# TM4C123GH6PM register map
Vendor: Texas Instruments; Series: TM4C; File version: 11073
CPU: CM4 r1p2, little endian, MPU, FPU, 3 interrupt priority bits
Registers are 32-bit, read-write, reset 0x1 unless marked. A register's access mark holds for its fields unless they carry their own. Offsets are from the block's base; [hi:lo] are bit positions; {n}, {i} and the like mark numbered series.

## TIMER0 — Register map for TIMER0 peripheral
Base 0x40030000; register names take the prefix TIMER0
Same registers: TIMER1 0x40031000 (register names take the prefix TIMER1), TIMER2 0x40032000 (register names take the prefix TIMER2), TIMER3 0x40033000 (register names take the prefix TIMER3), TIMER4 0x40034000 (register names take the prefix TIMER4), TIMER5 0x40035000 (register names take the prefix TIMER5), WTIMER1 0x40037000 (register names take the prefix WTIMER1), WTIMER2 0x4004C000 (register names take the prefix WTIMER2), WTIMER3 0x4004D000 (register names take the prefix WTIMER3), WTIMER4 0x4004E000 (register names take the prefix WTIMER4), WTIMER5 0x4004F000 (register names take the prefix WTIMER5)
0x00 CFG (reset mask 0x0) — GPTM Configuration
  [2:0] TIMER_CFG
    0=TIMER_CFG_32_BIT_TIMER (32-bit timer configuration); 1=TIMER_CFG_32_BIT_RTC (32-bit real-time clock (RTC) counter configuration); 4=TIMER_CFG_16_BIT (16-bit timer configuration. The function is controlled by bits 1:0 of GPTMTAMR and GPTMTBMR)
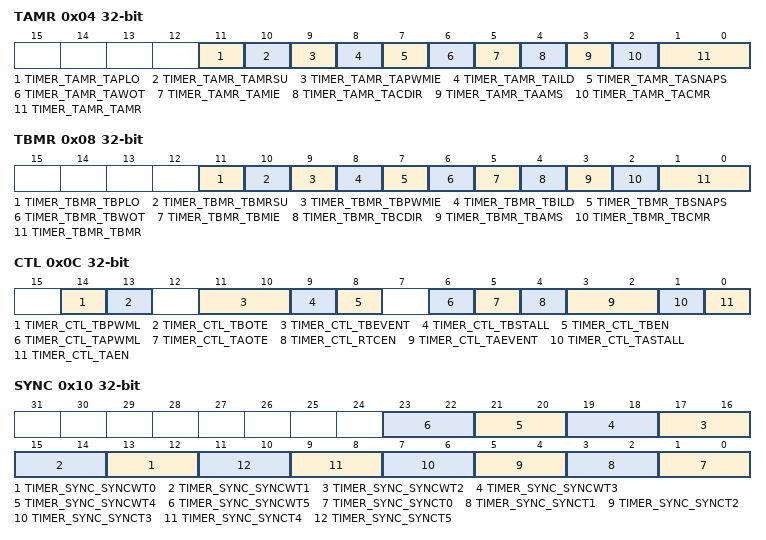
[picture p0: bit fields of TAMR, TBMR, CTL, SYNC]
0x04 TAMR (reset mask 0x0) — GPTM Timer A Mode
  [11] TIMER_TAMR_TAPLO — GPTM Timer A PWM Legacy Operation
  [10] TIMER_TAMR_TAMRSU — GPTM Timer A Match Register Update
  [9] TIMER_TAMR_TAPWMIE — GPTM Timer A PWM Interrupt Enable
  [8] TIMER_TAMR_TAILD — GPTM Timer A Interval Load Write
  [7] TIMER_TAMR_TASNAPS — GPTM Timer A Snap-Shot Mode
  [6] TIMER_TAMR_TAWOT — GPTM Timer A Wait-on-Trigger
  [5] TIMER_TAMR_TAMIE — GPTM Timer A Match Interrupt Enable
  [4] TIMER_TAMR_TACDIR — GPTM Timer A Count Direction
  [3] TIMER_TAMR_TAAMS — GPTM Timer A Alternate Mode Select
  [2] TIMER_TAMR_TACMR — GPTM Timer A Capture Mode
  [1:0] TIMER_TAMR_TAMR — GPTM Timer A Mode
    1=TIMER_TAMR_TAMR_1_SHOT (One-Shot Timer mode); 2=TIMER_TAMR_TAMR_PERIOD (Periodic Timer mode); 3=TIMER_TAMR_TAMR_CAP (Capture mode)
0x08 TBMR (reset mask 0x0) — GPTM Timer B Mode
  [11] TIMER_TBMR_TBPLO — GPTM Timer B PWM Legacy Operation
  [10] TIMER_TBMR_TBMRSU — GPTM Timer B Match Register Update
  [9] TIMER_TBMR_TBPWMIE — GPTM Timer B PWM Interrupt Enable
  [8] TIMER_TBMR_TBILD — GPTM Timer B Interval Load Write
  [7] TIMER_TBMR_TBSNAPS — GPTM Timer B Snap-Shot Mode
  [6] TIMER_TBMR_TBWOT — GPTM Timer B Wait-on-Trigger
  [5] TIMER_TBMR_TBMIE — GPTM Timer B Match Interrupt Enable
  [4] TIMER_TBMR_TBCDIR — GPTM Timer B Count Direction
  [3] TIMER_TBMR_TBAMS — GPTM Timer B Alternate Mode Select
  [2] TIMER_TBMR_TBCMR — GPTM Timer B Capture Mode
  [1:0] TIMER_TBMR_TBMR — GPTM Timer B Mode
    1=TIMER_TBMR_TBMR_1_SHOT (One-Shot Timer mode); 2=TIMER_TBMR_TBMR_PERIOD (Periodic Timer mode); 3=TIMER_TBMR_TBMR_CAP (Capture mode)
0x0C CTL (reset mask 0x0) — GPTM Control
  [14] TIMER_CTL_TBPWML — GPTM Timer B PWM Output Level
  [13] TIMER_CTL_TBOTE — GPTM Timer B Output Trigger Enable
  [11:10] TIMER_CTL_TBEVENT — GPTM Timer B Event Mode
    0=TIMER_CTL_TBEVENT_POS (Positive edge); 1=TIMER_CTL_TBEVENT_NEG (Negative edge); 3=TIMER_CTL_TBEVENT_BOTH (Both edges)
  [9] TIMER_CTL_TBSTALL — GPTM Timer B Stall Enable
  [8] TIMER_CTL_TBEN — GPTM Timer B Enable
  [6] TIMER_CTL_TAPWML — GPTM Timer A PWM Output Level
  [5] TIMER_CTL_TAOTE — GPTM Timer A Output Trigger Enable
  [4] TIMER_CTL_RTCEN — GPTM RTC Stall Enable
  [3:2] TIMER_CTL_TAEVENT — GPTM Timer A Event Mode
    0=TIMER_CTL_TAEVENT_POS (Positive edge); 1=TIMER_CTL_TAEVENT_NEG (Negative edge); 3=TIMER_CTL_TAEVENT_BOTH (Both edges)
  [1] TIMER_CTL_TASTALL — GPTM Timer A Stall Enable
  [0] TIMER_CTL_TAEN — GPTM Timer A Enable
0x10 SYNC (reset mask 0x0) — GPTM Synchronize
  [2n+13:2n+12] TIMER_SYNC_SYNCWT{n} (n=0..5) — Synchronize GPTM 32/64-Bit Timer {n}
    0=TIMER_SYNC_SYNCWT{n}_NONE (GPTM 32/64-Bit Timer {n} is not affected); 1=TIMER_SYNC_SYNCWT{n}_TA (A timeout event for Timer A of GPTM 32/64-Bit Timer {n} is triggered); 2=TIMER_SYNC_SYNCWT{n}_TB (A timeout event for Timer B of GPTM 32/64-Bit Timer {n} is triggered); 3=TIMER_SYNC_SYNCWT{n}_TATB (A timeout event for both Timer A and Timer B of GPTM 32/64-Bit Timer {n} is triggered)
  [2n+1:2n] TIMER_SYNC_SYNCT{n} (n=0..5) — Synchronize GPTM 16/32-Bit Timer {n}
    0=TIMER_SYNC_SYNCT{n}_NONE (GPTM 16/32-Bit Timer {n} is not affected); 1=TIMER_SYNC_SYNCT{n}_TA (A timeout event for Timer A of GPTM 16/32-Bit Timer {n} is triggered); 2=TIMER_SYNC_SYNCT{n}_TB (A timeout event for Timer B of GPTM 16/32-Bit Timer {n} is triggered); 3=TIMER_SYNC_SYNCT{n}_TATB (A timeout event for both Timer A and Timer B of GPTM 16/32-Bit Timer {n} is triggered)
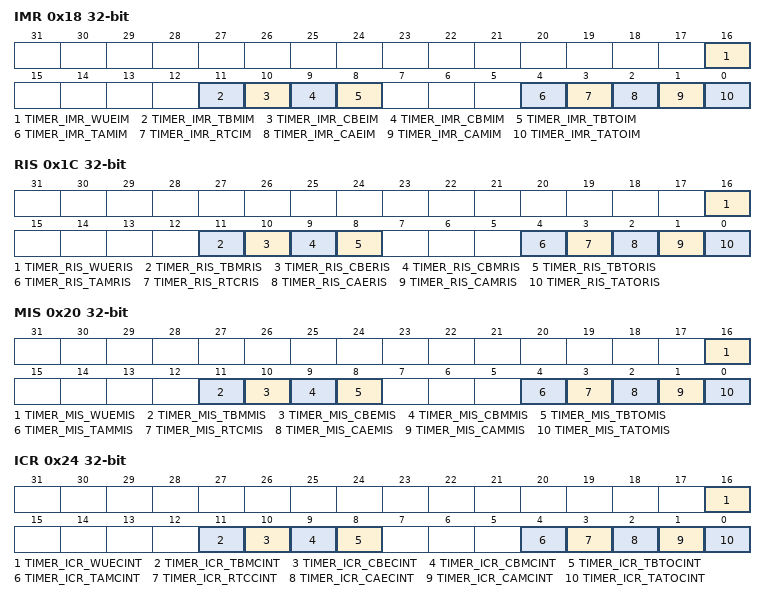
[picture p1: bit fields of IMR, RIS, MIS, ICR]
0x18 IMR (reset mask 0x0) — GPTM Interrupt Mask
  [16] TIMER_IMR_WUEIM — GPTM Write Update Error Interrupt Mask
  [11] TIMER_IMR_TBMIM — GPTM Timer B Match Interrupt Mask
  [10] TIMER_IMR_CBEIM — GPTM Timer B Capture Mode Event Interrupt Mask
  [9] TIMER_IMR_CBMIM — GPTM Timer B Capture Mode Match Interrupt Mask
  [8] TIMER_IMR_TBTOIM — GPTM Timer B Time-Out Interrupt Mask
  [4] TIMER_IMR_TAMIM — GPTM Timer A Match Interrupt Mask
  [3] TIMER_IMR_RTCIM — GPTM RTC Interrupt Mask
  [2] TIMER_IMR_CAEIM — GPTM Timer A Capture Mode Event Interrupt Mask
  [1] TIMER_IMR_CAMIM — GPTM Timer A Capture Mode Match Interrupt Mask
  [0] TIMER_IMR_TATOIM — GPTM Timer A Time-Out Interrupt Mask
0x1C RIS (reset mask 0x0) — GPTM Raw Interrupt Status
  [16] TIMER_RIS_WUERIS — GPTM Write Update Error Raw Interrupt
  [11] TIMER_RIS_TBMRIS — GPTM Timer B Match Raw Interrupt
  [10] TIMER_RIS_CBERIS — GPTM Timer B Capture Mode Event Raw Interrupt
  [9] TIMER_RIS_CBMRIS — GPTM Timer B Capture Mode Match Raw Interrupt
  [8] TIMER_RIS_TBTORIS — GPTM Timer B Time-Out Raw Interrupt
  [4] TIMER_RIS_TAMRIS — GPTM Timer A Match Raw Interrupt
  [3] TIMER_RIS_RTCRIS — GPTM RTC Raw Interrupt
  [2] TIMER_RIS_CAERIS — GPTM Timer A Capture Mode Event Raw Interrupt
  [1] TIMER_RIS_CAMRIS — GPTM Timer A Capture Mode Match Raw Interrupt
  [0] TIMER_RIS_TATORIS — GPTM Timer A Time-Out Raw Interrupt
0x20 MIS (reset mask 0x0) — GPTM Masked Interrupt Status
  [16] TIMER_MIS_WUEMIS — GPTM Write Update Error Masked Interrupt
  [11] TIMER_MIS_TBMMIS — GPTM Timer B Match Masked Interrupt
  [10] TIMER_MIS_CBEMIS — GPTM Timer B Capture Mode Event Masked Interrupt
  [9] TIMER_MIS_CBMMIS — GPTM Timer B Capture Mode Match Masked Interrupt
  [8] TIMER_MIS_TBTOMIS — GPTM Timer B Time-Out Masked Interrupt
  [4] TIMER_MIS_TAMMIS — GPTM Timer A Match Masked Interrupt
  [3] TIMER_MIS_RTCMIS — GPTM RTC Masked Interrupt
  [2] TIMER_MIS_CAEMIS — GPTM Timer A Capture Mode Event Masked Interrupt
  [1] TIMER_MIS_CAMMIS — GPTM Timer A Capture Mode Match Masked Interrupt
  [0] TIMER_MIS_TATOMIS — GPTM Timer A Time-Out Masked Interrupt
0x24 ICR wo (reset mask 0x0) — GPTM Interrupt Clear
  [16] TIMER_ICR_WUECINT — 32/64-Bit GPTM Write Update Error Interrupt Clear
  [11] TIMER_ICR_TBMCINT — GPTM Timer B Match Interrupt Clear
  [10] TIMER_ICR_CBECINT — GPTM Timer B Capture Mode Event Interrupt Clear
  [9] TIMER_ICR_CBMCINT — GPTM Timer B Capture Mode Match Interrupt Clear
  [8] TIMER_ICR_TBTOCINT — GPTM Timer B Time-Out Interrupt Clear
  [4] TIMER_ICR_TAMCINT — GPTM Timer A Match Interrupt Clear
  [3] TIMER_ICR_RTCCINT — GPTM RTC Interrupt Clear
  [2] TIMER_ICR_CAECINT — GPTM Timer A Capture Mode Event Interrupt Clear
  [1] TIMER_ICR_CAMCINT — GPTM Timer A Capture Mode Match Interrupt Clear
  [0] TIMER_ICR_TATOCINT — GPTM Timer A Time-Out Raw Interrupt
0x28 TAILR (reset mask 0x0) — GPTM Timer A Interval Load
0x2C TBILR (reset mask 0x0) — GPTM Timer B Interval Load
0x30 TAMATCHR (reset mask 0x0) — GPTM Timer A Match
0x34 TBMATCHR (reset mask 0x0) — GPTM Timer B Match
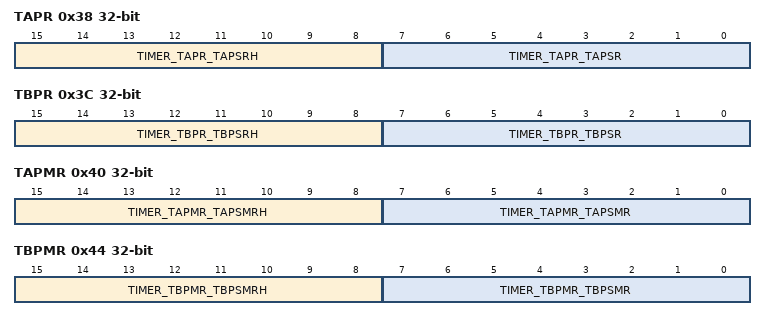
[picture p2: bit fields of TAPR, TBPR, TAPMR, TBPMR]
0x38 TAPR (reset mask 0x0) — GPTM Timer A Prescale
  [15:8] TIMER_TAPR_TAPSRH — GPTM Timer A Prescale High Byte
  [7:0] TIMER_TAPR_TAPSR — GPTM Timer A Prescale
0x3C TBPR (reset mask 0x0) — GPTM Timer B Prescale
  [15:8] TIMER_TBPR_TBPSRH — GPTM Timer B Prescale High Byte
  [7:0] TIMER_TBPR_TBPSR — GPTM Timer B Prescale
0x40 TAPMR (reset mask 0x0) — GPTM TimerA Prescale Match
  [15:8] TIMER_TAPMR_TAPSMRH — GPTM Timer A Prescale Match High Byte
  [7:0] TIMER_TAPMR_TAPSMR — GPTM TimerA Prescale Match
0x44 TBPMR (reset mask 0x0) — GPTM TimerB Prescale Match
  [15:8] TIMER_TBPMR_TBPSMRH — GPTM Timer B Prescale Match High Byte
  [7:0] TIMER_TBPMR_TBPSMR — GPTM TimerB Prescale Match
0x48 TAR (reset mask 0x0) — GPTM Timer A
0x4C TBR (reset mask 0x0) — GPTM Timer B
0x50 TAV (reset mask 0x0) — GPTM Timer A Value
0x54 TBV (reset mask 0x0) — GPTM Timer B Value
0x58 RTCPD (reset mask 0x0) — GPTM RTC Predivide
  [15:0] TIMER_RTCPD_RTCPD — RTC Predivide Counter Value
0x5C TAPS (reset mask 0x0) — GPTM Timer A Prescale Snapshot
  [15:0] TIMER_TAPS_PSS — GPTM Timer A Prescaler Snapshot
0x60 TBPS (reset mask 0x0) — GPTM Timer B Prescale Snapshot
  [15:0] TIMER_TBPS_PSS — GPTM Timer A Prescaler Value
0x64 TAPV (reset mask 0x0) — GPTM Timer A Prescale Value
  [15:0] TIMER_TAPV_PSV — GPTM Timer A Prescaler Value
0x68 TBPV (reset mask 0x0) — GPTM Timer B Prescale Value
  [15:0] TIMER_TBPV_PSV — GPTM Timer B Prescaler Value
0xFC0 PP (reset mask 0x0) — GPTM Peripheral Properties
  [3:0] TIMER_PP_SIZE — Count Size
    0=Timer A and Timer B counters are 16 bits each with an 8-bit prescale counter; 1=Timer A and Timer B counters are 32 bits each with a 16-bit prescale counter

## WTIMER0 — Register map for WTIMER0 peripheral
Base 0x40036000; register names take the prefix WTIMER0
Registers as TIMER0.
